# SYSCTRL_GENERAL_CORE register map
Vendor: Texas Instruments
Peripheral module from a debugger description file (folder omap4460).
Registers are 32-bit, access per field, reset values left out (the file's numbers can be read two ways) unless marked. A register's access mark holds for its fields unless they carry their own. Offsets are as the file gives them; lines under a group give offsets from that group; [hi:lo] are bit positions; {n}, {i} and the like mark numbered series; 'fields as' and 'values as' point back to an identical list; <NAME> marks a mode.

## SYSCTRL_GENERAL_CORE
0x00 CONTROL_GEN_CORE_REVISION ro — Control module instance revision identifier
  [31:0] REVISION — IP Revision
0x04 CONTROL_GEN_CORE_HWINFO ro — Information about the IP module hardware configuration
  [31:0] IP_HWINFO — IP-module dependent
0x10 CONTROL_GEN_CORE_SYSCONFIG — Access conditions. Read: unrestricted, Write: unrestricted
  [3:2] IP_SYSCONFIG_IDLEMODE rw — Select the local clock-gating strategy0x2,0x3: Clock is automatically gated when there is no access to the Control Module through L4-interconnect .
    0=Clock is manually gated; 1=Clock is manually enabled
0x200 CONTROL_STD_FUSE_DIE_ID_0 ro — Die ID Register - Part 0. Access conditions. Read: unrestricted
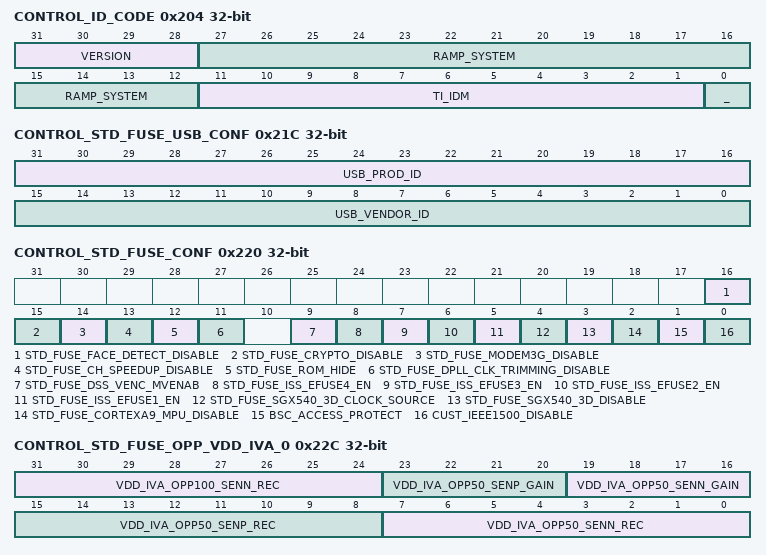
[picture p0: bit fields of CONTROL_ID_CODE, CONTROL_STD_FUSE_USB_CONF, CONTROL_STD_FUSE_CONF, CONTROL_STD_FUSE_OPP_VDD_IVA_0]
0x204 CONTROL_ID_CODE ro — ID_CODE Key Register Access conditions. Read: unrestricted
  [31:28] VERSION — Revision number
  [27:12] RAMP_SYSTEM — Ramp system number
  [11:1] TI_IDM — Manufacturer identity(TI)
  [0] _ — Always set to 1
{0x204+4i} CONTROL_STD_FUSE_DIE_ID_{i} ro (i=1..3) — Die ID Register - Part {i}. Access conditions. Read: unrestricted
0x214 CONTROL_STD_FUSE_PROD_ID_0 ro — Prod ID Register - Part 0. This register shows the device type. Access conditions. Read: unrestricted
  [7:0] DEVICE_TYPE — Define the device type 0xF0 = GP device Other values = Reserved
0x218 CONTROL_STD_FUSE_PROD_ID_1 ro — Prod ID Register - Part 1.This register shows the device type. Access conditions. Read: unrestricted
  [17:16] SILICON_TYPE — Define the silicon performance type
0x21C CONTROL_STD_FUSE_USB_CONF ro — Standard Fuse conf [31:0]. Register shows part of the chip standard eFuse configuration. Reading at the address of one of these registers provides a direct view into a part of the eFuse chain. Access conditions. Read: unrestricted, Write: unrestricted
  [31:16] USB_PROD_ID — USB Product Identification
  [15:0] USB_VENDOR_ID — USB Vendor Identification
0x220 CONTROL_STD_FUSE_CONF ro — Standard fuse configuration register. The register shows part of the chip eFuse configuration on the L4 interface. Reading at the address of one of these registers provides a direct view into a part of the eFuse chain. Access conditions. Read only
  [16] STD_FUSE_FACE_DETECT_DISABLE — Disables face detect
    0=STD_FUSE_FACE_DETECT_DISABLE_0_r (Enables face detect); 1=STD_FUSE_FACE_DETECT_DISABLE_1_r (Disables face detect)
  [15] STD_FUSE_CRYPTO_DISABLE — Disables cryptographic modules
    0=STD_FUSE_CRYPTO_DISABLE_0_r (Enables cryptrographic modules); 1=STD_FUSE_CRYPTO_DISABLE_1_r (Disables cryptrographic modules)
  [14] STD_FUSE_MODEM3G_DISABLE — Disables the 3G modem
    0=STD_FUSE_MODEM3G_DISABLE_0_r (Enables 3G modem); 1=STD_FUSE_MODEM3G_DISABLE_1_r (Disables 3G modem)
  [13] STD_FUSE_CH_SPEEDUP_DISABLE — ROM code settings for configuration header block and speedup block. Only software access (no hardware access).
    0=STD_FUSE_CH_SPEEDUP_DISABLE_0_r (Enables CH and speedup); 1=STD_FUSE_CH_SPEEDUP_DISABLE_1_r (Disables CH and speedup)
  [12] STD_FUSE_ROM_HIDE — MPU BOOT ROM space (4-KB ROM code protection)
    0=STD_FUSE_ROM_HIDE_0_r (BOOT ROM space is 128KB.); 1=STD_FUSE_ROM_HIDE_1_r (BOOT ROM upper 4-KB region becomes reserved.)
  [11] STD_FUSE_DPLL_CLK_TRIMMING_DISABLE — Controls DPLLs
    0=STD_FUSE_DPLL_CLK_TRIMMING_DISABLE_0_r (Enables DPLL trimming); 1=STD_FUSE_DPLL_CLK_TRIMMING_DISABLE_1_r (Disables DPLL trimming)
  [9] STD_FUSE_DSS_VENC_MVENAB — Enables implementation-specific features. Controls DSS_VENC_MVENAB.
    0=STD_FUSE_DSS_VENC_MVENAB_0_r (Disables DSS_VENC_MVENAB); 1=STD_FUSE_DSS_VENC_MVENAB_1_r (Enables DSS_VENC_MVENAB)
  [8] STD_FUSE_ISS_EFUSE4_EN — Enables implementation-specific features. Controls ISS.EFUSE4_EN. Sets to 0.
    0=STD_FUSE_ISS_EFUSE4_EN_0_r (Disables ISS EFUSE4); 1=STD_FUSE_ISS_EFUSE4_EN_1_r (Enables ISS EFUSE4)
  [7] STD_FUSE_ISS_EFUSE3_EN — Enables implementation specific features. Controls ISS.EFUSE3_EN. Sets to 0.
    0=STD_FUSE_ISS_EFUSE3_EN_0_r (Disables ISS EFUSE3); 1=STD_FUSE_ISS_EFUSE3_EN_1_r (Enables ISS EFUSE3)
  [6] STD_FUSE_ISS_EFUSE2_EN — Enables implementation-specific features. Controls ISS.EFUSE2_EN. Sets to 0.
    0=STD_FUSE_ISS_EFUSE2_EN_0_r (Disables ISS EFUSE2); 1=STD_FUSE_ISS_EFUSE2_EN_1_r (Enables ISS EFUSE2)
  [5] STD_FUSE_ISS_EFUSE1_EN — Enables implementation-specific features. Controls ISS.EFUSE1_EN. Sets to 1.
    0=STD_FUSE_ISS_EFUSE1_EN_0_r (Disables ISS EFUSE1); 1=STD_FUSE_ISS_EFUSE1_EN_1_r (Enables ISS EFUSE1)
  [4] STD_FUSE_SGX540_3D_CLOCK_SOURCE — Force 3D graphic engine clock source
  [3] STD_FUSE_SGX540_3D_DISABLE — Disable the 3D Gx engine (SGX540)
    0=STD_FUSE_SGX540_3D_DISABLE_0_r (Enables SGX); 1=STD_FUSE_SGX540_3D_DISABLE_1_r (Disables SGX)
  [2] STD_FUSE_CORTEXA9_MPU_DISABLE — Configures Cortex-A9 MPU boot mode. It disables one Cortex-A9 core.
    0=STD_FUSE_CORTEXA9_MPU_DISABLE_0_r (Boot SMP mode); 1=STD_FUSE_CORTEXA9_MPU_DISABLE_1_r (Boot IP mode)
  [1] BSC_ACCESS_PROTECT — Reserved for bsc_access protect
  [0] CUST_IEEE1500_DISABLE — Customer eFuse control/IEEE1500 access path disable
0x228 CONTROL_STD_FUSE_OPP_VDD_WKUP ro — Standard Fuse OPP VDD_WKUP [31:0]. Register shows part of the chip standard eFuse configuration. Reading at the address of one of these registers provides a direct view into a part of the eFuse chain. Access conditions. Read: unrestricted, Write: unrestricted
  [31:0] STD_FUSE_OPP_VDD_WKUP
0x22C CONTROL_STD_FUSE_OPP_VDD_IVA_0 ro — Standard Fuse OPP VDD_IVA_0. Register shows part of the chip eFuse configuration on the L4 interface. Reading at the address of one of these registers provides a direct view into a part of the eFuse chain. Access conditions. Read: unrestricted, Write: unrestricted
  [31:24] VDD_IVA_OPP100_SENN_REC — Voltage domain VDD_IVA OPP100 [7:0] from Standard Fuse
  [23:20] VDD_IVA_OPP50_SENP_GAIN — Voltage domain VDD_IVA OPP50 [23:20] from Standard Fuse
  [19:16] VDD_IVA_OPP50_SENN_GAIN — Voltage domain VDD_IVA OPP50 [19:16] from Standard Fuse
  [15:8] VDD_IVA_OPP50_SENP_REC — Voltage domain VDD_IVA OPP50 [15:8] from Standard Fuse
  [7:0] VDD_IVA_OPP50_SENN_REC — Voltage domain VDD_IVA OPP50 [7:0] from Standard Fuse
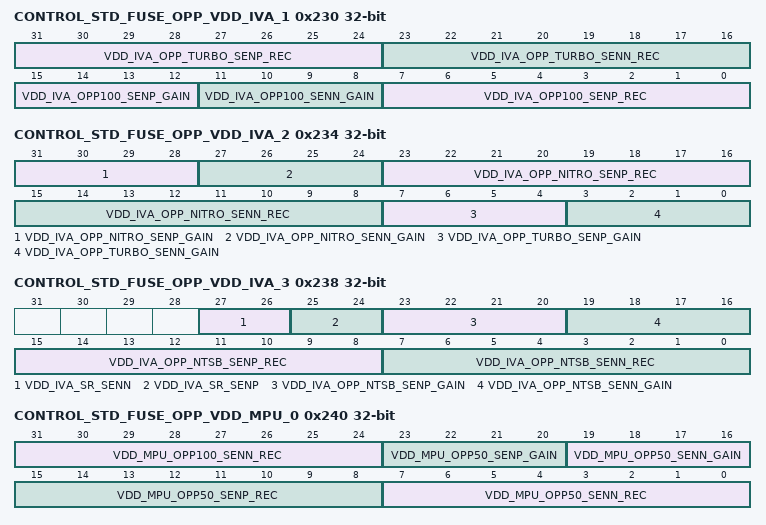
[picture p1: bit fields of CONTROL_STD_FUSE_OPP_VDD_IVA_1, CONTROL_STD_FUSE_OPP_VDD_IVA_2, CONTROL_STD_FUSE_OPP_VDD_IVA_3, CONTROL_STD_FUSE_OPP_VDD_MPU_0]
0x230 CONTROL_STD_FUSE_OPP_VDD_IVA_1 ro — Standard Fuse OPP VDD_IVA_1. Register shows part of the chip eFuse configuration on the L4 interface. Reading at the address of one of these registers provides a direct view into a part of the eFuse chain. Access conditions. Read: unrestricted, Write: unrestricted
  [31:24] VDD_IVA_OPP_TURBO_SENP_REC — Voltage domain VDD_IVA OPP_TURBO [15:8] from Standard Fuse
  [23:16] VDD_IVA_OPP_TURBO_SENN_REC — Voltage domain VDD_IVA OPP_TURBO [7:0] from Standard Fuse
  [15:12] VDD_IVA_OPP100_SENP_GAIN — Voltage domain VDD_IVA OPP100 [23:20] from Standard Fuse
  [11:8] VDD_IVA_OPP100_SENN_GAIN — Voltage domain VDD_IVA OPP100 [19:16] from Standard Fuse
  [7:0] VDD_IVA_OPP100_SENP_REC — Voltage domain VDD_IVA OPP100 [15:8] from Standard Fuse
0x234 CONTROL_STD_FUSE_OPP_VDD_IVA_2 ro — Standard Fuse OPP VDD_IVA_2. Register shows part of the chip eFuse configuration on the L4 interface. Reading at the address of one of these registers provides a direct view into a part of the eFuse chain. Access conditions. Read: unrestricted, Write: unrestricted
  [31:28] VDD_IVA_OPP_NITRO_SENP_GAIN — Voltage domain VDD_IVA OPP_NITRO[23:20] from Standard Fuse
  [27:24] VDD_IVA_OPP_NITRO_SENN_GAIN — Voltage domain VDD_IVA OPP_NITRO[19:16] from Standard Fuse
  [23:16] VDD_IVA_OPP_NITRO_SENP_REC — Voltage domain VDD_IVA OPP_NITRO[15:8] from Standard Fuse
  [15:8] VDD_IVA_OPP_NITRO_SENN_REC — Voltage domain VDD_IVA OPP_NITRO[7:0] from Standard Fuse
  [7:4] VDD_IVA_OPP_TURBO_SENP_GAIN — Voltage domain VDD_IVA OPP_TURBO[23:20] from Standard Fuse
  [3:0] VDD_IVA_OPP_TURBO_SENN_GAIN — Voltage domain VDD_IVA OPP_TURBO[19:16] from Standard Fuse
0x238 CONTROL_STD_FUSE_OPP_VDD_IVA_3 ro — Standard Fuse OPP VDD_IVA_3. Register shows part of the chip eFuse configuration on the L4 interface. Reading at the address of one of these registers provides a direct view into a part of the eFuse chain. Access conditions. Read: unrestricted, Write: unrestricted
  [27:26] VDD_IVA_SR_SENN — VDD_IVA SmartReflex from Standard Fuse
  [25:24] VDD_IVA_SR_SENP — VDD_IVA SmartReflex from Standard Fuse
  [23:20] VDD_IVA_OPP_NTSB_SENP_GAIN — Voltage domain VDD_IVA OPP_NTSB[23:20] from Standard Fuse
  [19:16] VDD_IVA_OPP_NTSB_SENN_GAIN — Voltage domain VDD_IVA OPP_NTSB[19:16] from Standard Fuse
  [15:8] VDD_IVA_OPP_NTSB_SENP_REC — Voltage domain VDD_IVA OPP_NTSB[15:8] from Standard Fuse
  [7:0] VDD_IVA_OPP_NTSB_SENN_REC — Voltage domain VDD_IVA OPP_NTSB[7:0] from Standard Fuse
0x240 CONTROL_STD_FUSE_OPP_VDD_MPU_0 ro — Standard Fuse OPP VDD_MPU_0. Register shows part of the chip eFuse configuration on the L4 interface. Reading at the address of one of these registers provides a direct view into a part of the eFuse chain. Access conditions. Read: unrestricted, Write: unrestricted
  [31:24] VDD_MPU_OPP100_SENN_REC — Voltage domain VDD_MPU OPP100[7:0] from Standard Fuse
  [23:20] VDD_MPU_OPP50_SENP_GAIN — Voltage domain VDD_MPU OPP50[23:20] from Standard Fuse
  [19:16] VDD_MPU_OPP50_SENN_GAIN — Voltage domain VDD_MPU OPP50[19:16] from Standard Fuse
  [15:8] VDD_MPU_OPP50_SENP_REC — Voltage domain VDD_MPU OPP50[15:8] from Standard Fuse
  [7:0] VDD_MPU_OPP50_SENN_REC — Voltage domain VDD_MPU OPP50[7:0] from Standard Fuse
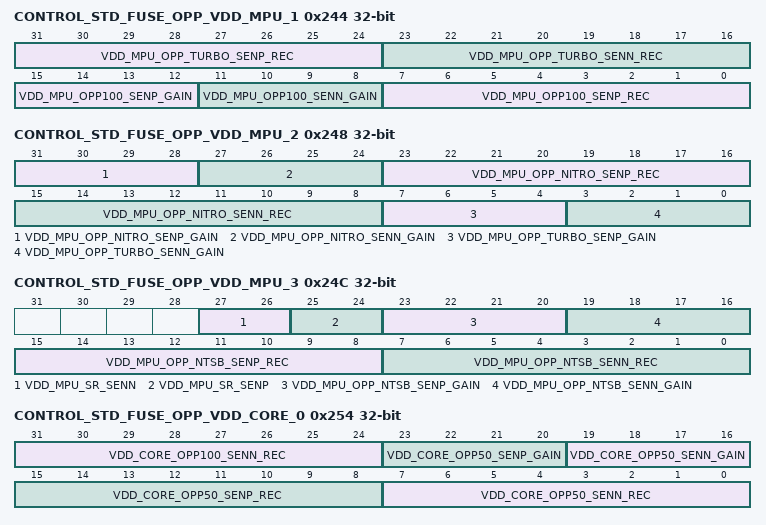
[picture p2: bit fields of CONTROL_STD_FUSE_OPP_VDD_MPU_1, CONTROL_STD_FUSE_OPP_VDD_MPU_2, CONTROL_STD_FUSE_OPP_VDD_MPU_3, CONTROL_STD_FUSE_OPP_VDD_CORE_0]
0x244 CONTROL_STD_FUSE_OPP_VDD_MPU_1 ro — Standard Fuse OPP VDD_MPU_1. Register shows part of the chip eFuse configuration on the L4 interface. Reading at the address of one of these registers provides a direct view into a part of the eFuse chain. Access conditions. Read: unrestricted, Write: unrestricted
  [31:24] VDD_MPU_OPP_TURBO_SENP_REC — Voltage domain VDD_MPU OPP_TURBO[15:8] from Standard Fuse
  [23:16] VDD_MPU_OPP_TURBO_SENN_REC — Voltage domain VDD_MPU OPP_TURBO[7:0] from Standard Fuse
  [15:12] VDD_MPU_OPP100_SENP_GAIN — Voltage domain VDD_MPU OPP100[23:20] from Standard Fuse
  [11:8] VDD_MPU_OPP100_SENN_GAIN — Voltage domain VDD_MPU OPP100[19:16] from Standard Fuse
  [7:0] VDD_MPU_OPP100_SENP_REC — Voltage domain VDD_MPU OPP100[15:8] from Standard Fuse
0x248 CONTROL_STD_FUSE_OPP_VDD_MPU_2 ro — Standard Fuse OPP VDD_MPU_2. Register shows part of the chip eFuse configuration on the L4 interface. Reading at the address of one of these registers provides a direct view into a part of the eFuse chain. Access conditions. Read: unrestricted, Write: unrestricted
  [31:28] VDD_MPU_OPP_NITRO_SENP_GAIN — Voltage domain VDD_MPU OPP_NITRO[23:20] from Standard Fuse
  [27:24] VDD_MPU_OPP_NITRO_SENN_GAIN — Voltage domain VDD_MPU OPP_NITRO[19:16] from Standard Fuse
  [23:16] VDD_MPU_OPP_NITRO_SENP_REC — Voltage domain VDD_MPU OPP_NITRO[15:8] from Standard Fuse
  [15:8] VDD_MPU_OPP_NITRO_SENN_REC — Voltage domain VDD_MPU OPP_NITRO[7:0] from Standard Fuse
  [7:4] VDD_MPU_OPP_TURBO_SENP_GAIN — Voltage domain VDD_MPU OPP_TURBO[23:20] from Standard Fuse
  [3:0] VDD_MPU_OPP_TURBO_SENN_GAIN — Voltage domain VDD_MPU OPP_TURBO[19:16] from Standard Fuse
0x24C CONTROL_STD_FUSE_OPP_VDD_MPU_3 ro — Standard Fuse OPP VDD_MPU_3. Register shows part of the chip eFuse configuration on the L4 interface. Reading at the address of one of these registers provides a direct view into a part of the eFuse chain. Access conditions. Read: unrestricted, Write: unrestricted
  [27:26] VDD_MPU_SR_SENN — VDD_MPU SmartReflex from Standard Fuse
  [25:24] VDD_MPU_SR_SENP — VDD_MPU SmartReflex from Standard Fuse
  [23:20] VDD_MPU_OPP_NTSB_SENP_GAIN — Voltage domain VDD_MPU OPP_NTSB[23:20] from Standard Fuse
  [19:16] VDD_MPU_OPP_NTSB_SENN_GAIN — Voltage domain VDD_MPU OPP_NTSB[19:16] from Standard Fuse
  [15:8] VDD_MPU_OPP_NTSB_SENP_REC — Voltage domain VDD_MPU OPP_NTSB[15:8] from Standard Fuse
  [7:0] VDD_MPU_OPP_NTSB_SENN_REC — Voltage domain VDD_MPU OPP_NTSB[7:0] from Standard Fuse
0x254 CONTROL_STD_FUSE_OPP_VDD_CORE_0 ro — Standard Fuse OPP VDD_CORE_0. Register shows part of the chip eFuse configuration on the L4 interface. Reading at the address of one of these registers provides a direct view into a part of the eFuse chain. Access conditions. Read: unrestricted, Write: unrestricted
  [31:24] VDD_CORE_OPP100_SENN_REC — Voltage domain VDD_CORE OPP100[7:0] from Standard Fuse
  [23:20] VDD_CORE_OPP50_SENP_GAIN — Voltage domain VDD_CORE OPP50 23:20] from Standard Fuse
  [19:16] VDD_CORE_OPP50_SENN_GAIN — Voltage domain VDD_CORE OPP50[19:16] from Standard Fuse
  [15:8] VDD_CORE_OPP50_SENP_REC — Voltage domain VDD_CORE OPP50[15:8] from Standard Fuse
  [7:0] VDD_CORE_OPP50_SENN_REC — Voltage domain VDD_CORE OPP50[7:0] from Standard Fuse
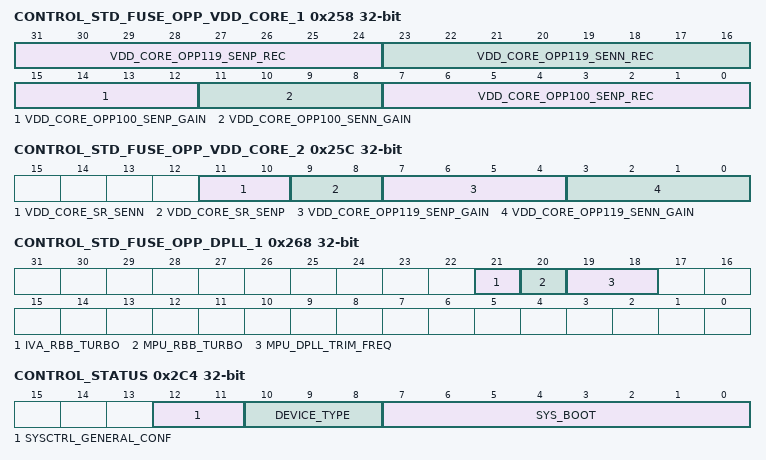
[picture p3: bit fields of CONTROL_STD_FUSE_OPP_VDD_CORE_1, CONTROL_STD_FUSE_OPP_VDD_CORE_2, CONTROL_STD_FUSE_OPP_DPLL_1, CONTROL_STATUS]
0x258 CONTROL_STD_FUSE_OPP_VDD_CORE_1 ro — Standard Fuse OPP VDD_CORE_1. Register shows part of the chip eFuse configuration on the L4 interface. Reading at the address of one of these registers provides a direct view into a part of the eFuse chain. Access conditions. Read: unrestricted, Write: unrestricted
  [31:24] VDD_CORE_OPP119_SENP_REC — Voltage domain VDD_CORE OPP119[15:8] from Standard Fuse (overdrive mode)
  [23:16] VDD_CORE_OPP119_SENN_REC — Voltage domain VDD_CORE OPP119[7:0] from Standard Fuse (overdrive mode)
  [15:12] VDD_CORE_OPP100_SENP_GAIN — Voltage domain VDD_CORE OPP100[23:20] from Standard Fuse
  [11:8] VDD_CORE_OPP100_SENN_GAIN — Voltage domain VDD_CORE OPP100[19:16] from Standard Fuse
  [7:0] VDD_CORE_OPP100_SENP_REC — Voltage domain VDD_CORE OPP100[15:8] from Standard Fuse
0x25C CONTROL_STD_FUSE_OPP_VDD_CORE_2 ro — Standard Fuse OPP VDD_CORE_2. Register shows part of the chip eFuse configuration on the L4 interface. Reading at the address of one of these registers provides a direct view into a part of the eFuse chain. Access conditions. Read: unrestricted, Write: unrestricted
  [11:10] VDD_CORE_SR_SENN — VDD_CORE SmartReflex from Standard Fuse
  [9:8] VDD_CORE_SR_SENP — VDD_CORE SmartReflex from Standard Fuse
  [7:4] VDD_CORE_OPP119_SENP_GAIN — Voltage domain VDD_CORE OPP119[23:20] from Standard Fuse (overdrive mode)
  [3:0] VDD_CORE_OPP119_SENN_GAIN — Voltage domain VDD_CORE OPP119[19:16] from Standard Fuse (overdrive mode)
0x260 CONTROL_STD_FUSE_OPP_BGAP ro — Standard Fuse OPP BGAP. Register shows part of the chip standard eFuse configuration. Reading at the address of one of these registers provides a direct view into a part of the eFuse chain. Access conditions. Read: unrestricted, Write: unrestricted
  [31:0] STD_FUSE_OPP_BGAP
0x264 CONTROL_STD_FUSE_OPP_DPLL_0 ro — Standard Fuse OPP DPLL. Register shows part of the chip standard eFuse configuration. Reading at the address of one of these registers provides a direct view into a part of the eFuse chain. Access conditions. Read: unrestricted, Write: unrestricted
  [31:0] STD_FUSE_OPP_DPLL_0
0x268 CONTROL_STD_FUSE_OPP_DPLL_1 ro — Standard Fuse OPP DPLL. Register shows part of the chip standard eFuse configuration. Reading at the address of one of these registers provides a direct view into a part of the eFuse chain. Access conditions. Read: unrestricted, Write: unrestricted
  [21] IVA_RBB_TURBO — If trimmed, ABB (Adaptive Body Bias) Set2 mode can be enabled at OPP TURBO on IVA
    0=IVA ABB Set2 voltage is NOT trimmed; 1=IVA ABB Set2 voltage is trimmed
  [20] MPU_RBB_TURBO — If trimmed, ABB Set2 mode can be enabled at OPP TURBO on MPU.
    0=MPU ABB Set2 voltage is NOT trimmed; 1=MPU ABB Set2 voltage is trimmed
  [19:18] MPU_DPLL_TRIM_FREQ — Lock frequency at which the MPU DPLL is trimmed. The DPLL can be locked at any valid frequencies up to this value.
    0=2 GHz; 1=2.4 GHz; 3=3 GHz
0x2C4 CONTROL_STATUS ro — Control Module Status Register Access conditions. Read: unrestricted, Write: unrestricted
  [12:11] SYSCTRL_GENERAL_CONF — Sysctrl_General_ IP configuration
    1=SYSCTRL_GENERAL_CONF_1_r (SMP configuration)
  [10:8] DEVICE_TYPE — Device type captured at reset time Device type value sampled at power-on reset.
    3=DEVICE_TYPE_3_r (General Purpose (GP))
  [7:0] SYS_BOOT — Sys.Boot pins state captured at reset time Sys.Boot pin values sampled at power-on reset
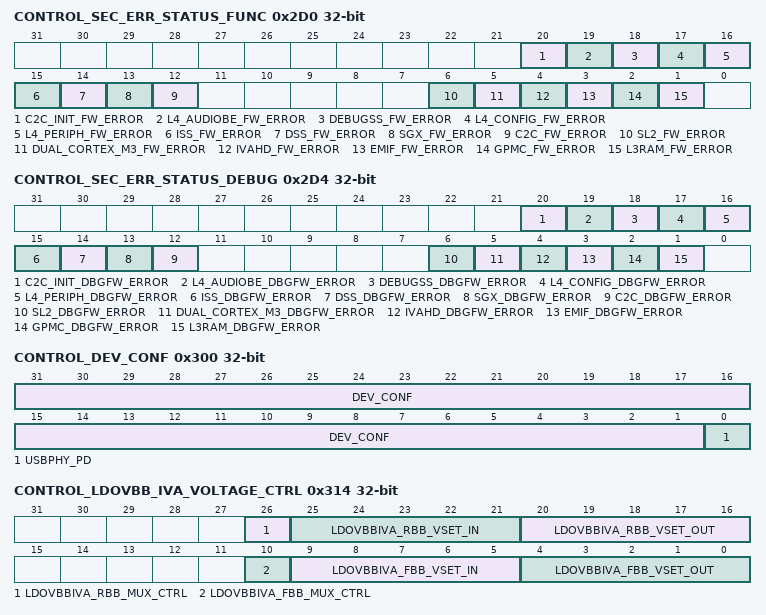
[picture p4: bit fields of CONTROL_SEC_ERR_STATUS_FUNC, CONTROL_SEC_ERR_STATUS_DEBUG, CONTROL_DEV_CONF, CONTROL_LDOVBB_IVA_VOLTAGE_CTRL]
0x2D0 CONTROL_SEC_ERR_STATUS_FUNC ro — Firewall Error Status functional Register Access conditions. Read Only
  [all] fields
    0=No error from firewall; 1=Error from firewall
  [20] C2C_INIT_FW_ERROR — C2C init firewall. MID config: unused (reserved)
  [19] L4_AUDIOBE_FW_ERROR — L4 AudioBE firewall
  [18] DEBUGSS_FW_ERROR — DebugSS firewall
  [17] L4_CONFIG_FW_ERROR — L4 Config firewall
  [16] L4_PERIPH_FW_ERROR — L4 PER firewall
  [15] ISS_FW_ERROR — ISS firewall
  [14] DSS_FW_ERROR — DSS firewall
  [13] SGX_FW_ERROR — SGX firewall
  [12] C2C_FW_ERROR — C2C firewall. MID config: unused (reserved).
  [6] SL2_FW_ERROR — SL2 firewall
  [5] DUAL_CORTEX_M3_FW_ERROR — Dual Cortex M3 firewall
  [4] IVAHD_FW_ERROR — IVAHD firewall
  [3] EMIF_FW_ERROR — EMIF firewall
  [2] GPMC_FW_ERROR — GPMC firewall
  [1] L3RAM_FW_ERROR — L3RAM firewall
0x2D4 CONTROL_SEC_ERR_STATUS_DEBUG ro — Error Status debug Register. Read All / Write All. Access conditions. Read: unrestricted, Write: unrestricted
  [all] fields
    0=No error from firewall; 1=Error from firewall
  [20] C2C_INIT_DBGFW_ERROR — C2C init debug firewall. MID config: unused (reserved)
  [19] L4_AUDIOBE_DBGFW_ERROR — L4 AudioBE debug firewall
  [18] DEBUGSS_DBGFW_ERROR — DebugSS debug firewall
  [17] L4_CONFIG_DBGFW_ERROR — L4 Config debug firewall
  [16] L4_PERIPH_DBGFW_ERROR — L4 PER debug firewall
  [15] ISS_DBGFW_ERROR — ISS debug firewall
  [14] DSS_DBGFW_ERROR — DSS debug firewall
  [13] SGX_DBGFW_ERROR — SGX debug firewall
  [12] C2C_DBGFW_ERROR — C2C debug firewall. MID config: unused (reserved).
  [6] SL2_DBGFW_ERROR — SL2 debug firewall
  [5] DUAL_CORTEX_M3_DBGFW_ERROR — Dual Cortex M3 debug firewall
  [4] IVAHD_DBGFW_ERROR — IVAHD debug firewall
  [3] EMIF_DBGFW_ERROR — EMIF debug firewall
  [2] GPMC_DBGFW_ERROR — GPMC debug firewall
  [1] L3RAM_DBGFW_ERROR — L3RAM debug firewall
0x300 CONTROL_DEV_CONF rw — Device configuration register. Access conditions. Read: unrestricted, Write: unrestricted
  [31:1] DEV_CONF — Spare bits for device configuration.
  [0] USBPHY_PD — Power down entire USB phy (data, common module and UTMI). controls USB2PHYCORE.PD pin.
    0=Normal operation; 1=Power down the USB PHY
0x314 CONTROL_LDOVBB_IVA_VOLTAGE_CTRL — IVA Voltage Body Bias LDO control register Access conditions. Read: unrestricted, Write: unrestricted
  [26] LDOVBBIVA_RBB_MUX_CTRL rw — Override control of EFUSE Adaptive Body Bias set2 voltage value
    0=EFUSE value is used; 1=Override value is used
  [25:21] LDOVBBIVA_RBB_VSET_IN ro — EFUSE Adaptive Body Bias set2 voltage value
  [20:16] LDOVBBIVA_RBB_VSET_OUT rw — Override value for Adaptive Body Bias set2 voltage
  [10] LDOVBBIVA_FBB_MUX_CTRL rw — Override control of EFUSE Adaptive Body Bias Set1 voltage value
    0=EFUSE value is used; 1=Override value is used
  [9:5] LDOVBBIVA_FBB_VSET_IN ro — EFUSE Adaptive Body Bias Set1 voltage value
  [4:0] LDOVBBIVA_FBB_VSET_OUT rw — Override value for Adaptive Body Bias Set1 voltage
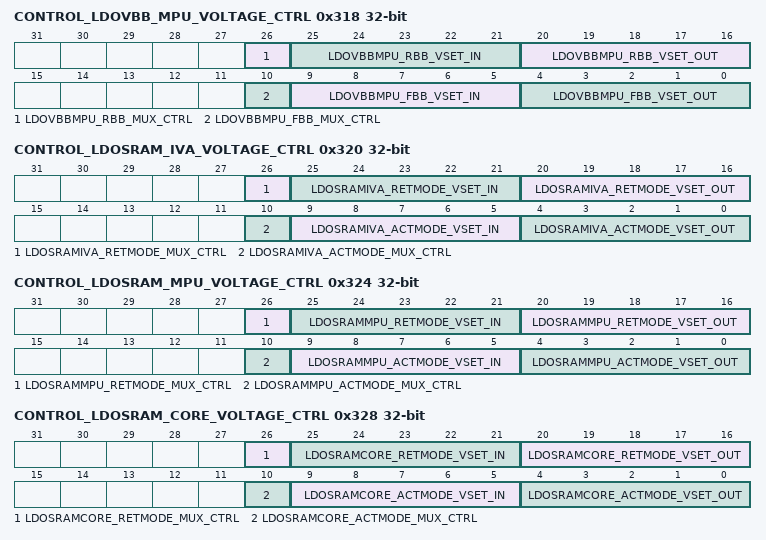
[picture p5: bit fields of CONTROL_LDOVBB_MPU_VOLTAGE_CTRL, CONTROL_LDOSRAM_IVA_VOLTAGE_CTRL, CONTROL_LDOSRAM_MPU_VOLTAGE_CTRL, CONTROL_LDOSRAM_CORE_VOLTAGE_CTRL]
0x318 CONTROL_LDOVBB_MPU_VOLTAGE_CTRL — MPU Voltage Body Bias LDO control register Access conditions. Read: unrestricted, Write: unrestricted
  [26] LDOVBBMPU_RBB_MUX_CTRL rw — Override control of EFUSE Adaptive Body Bias Set2 voltage value
    0=EFUSE value is used; 1=Override value is used
  [25:21] LDOVBBMPU_RBB_VSET_IN ro — EFUSE Adaptive Body Bias Set2 voltage value
  [20:16] LDOVBBMPU_RBB_VSET_OUT rw — Override value for Adaptive Body Bias Set2 voltage
  [10] LDOVBBMPU_FBB_MUX_CTRL rw — Override control of EFUSE Adaptive Body Bias Set1 voltage value
    0=EFUSE value is used; 1=Override value is used
  [9:5] LDOVBBMPU_FBB_VSET_IN ro — EFUSE Adaptive Body Bias Set1 voltage value
  [4:0] LDOVBBMPU_FBB_VSET_OUT rw — Override value for Adaptive Body Bias Set1 voltage
0x320 CONTROL_LDOSRAM_IVA_VOLTAGE_CTRL — IVA SRAM LDO control register Access conditions. Read: unrestricted, Write: unrestricted
  [26] LDOSRAMIVA_RETMODE_MUX_CTRL rw — Override control of EFUSE Retention Mode Voltage value
    0=efuse value is used; 1=override value is used
  [25:21] LDOSRAMIVA_RETMODE_VSET_IN ro — EFUSE Retention Mode Voltage value (vset[9:5])
  [20:16] LDOSRAMIVA_RETMODE_VSET_OUT rw — Override value for Retention Mode Voltage
  [10] LDOSRAMIVA_ACTMODE_MUX_CTRL rw — Override control of EFUSE Active Mode Voltage value
    0=efuse value is used; 1=override value is used
  [9:5] LDOSRAMIVA_ACTMODE_VSET_IN ro — EFUSE Active Mode Voltage value (vset[4:0])
  [4:0] LDOSRAMIVA_ACTMODE_VSET_OUT rw — Override value for Active Mode Voltage value
0x324 CONTROL_LDOSRAM_MPU_VOLTAGE_CTRL — MPU SRAM LDO control register Access conditions. Read: unrestricted, Write: unrestricted
  [26] LDOSRAMMPU_RETMODE_MUX_CTRL rw — Override control of EFUSE Retention Mode Voltage value
    0=efuse value is used; 1=override value is used
  [25:21] LDOSRAMMPU_RETMODE_VSET_IN ro — EFUSE Retention Mode Voltage value (vset[9:5])
  [20:16] LDOSRAMMPU_RETMODE_VSET_OUT rw — Override value for Retention Mode Voltage
  [10] LDOSRAMMPU_ACTMODE_MUX_CTRL rw — Override control of EFUSE Active Mode Voltage value
    0=efuse value is used; 1=override value is used
  [9:5] LDOSRAMMPU_ACTMODE_VSET_IN ro — EFUSE Active Mode Voltage value (vset[4:0])
  [4:0] LDOSRAMMPU_ACTMODE_VSET_OUT rw — Override value for Active Mode Voltage value
0x328 CONTROL_LDOSRAM_CORE_VOLTAGE_CTRL — Core SRAM LDO control register Access conditions. Read: unrestricted, Write: unrestricted
  [26] LDOSRAMCORE_RETMODE_MUX_CTRL rw — Override control of EFUSE Retention Mode Voltage value
    0=efuse value is used; 1=override value is used
  [25:21] LDOSRAMCORE_RETMODE_VSET_IN ro — EFUSE Retention Mode Voltage value (vset[9:5])
  [20:16] LDOSRAMCORE_RETMODE_VSET_OUT rw — Override value for Retention Mode Voltage
  [10] LDOSRAMCORE_ACTMODE_MUX_CTRL rw — Override control of EFUSE Active Mode Voltage value
    0=efuse value is used; 1=override value is used
  [9:5] LDOSRAMCORE_ACTMODE_VSET_IN ro — EFUSE Active Mode Voltage value (vset[4:0])
  [4:0] LDOSRAMCORE_ACTMODE_VSET_OUT rw — Override value for Active Mode Voltage value
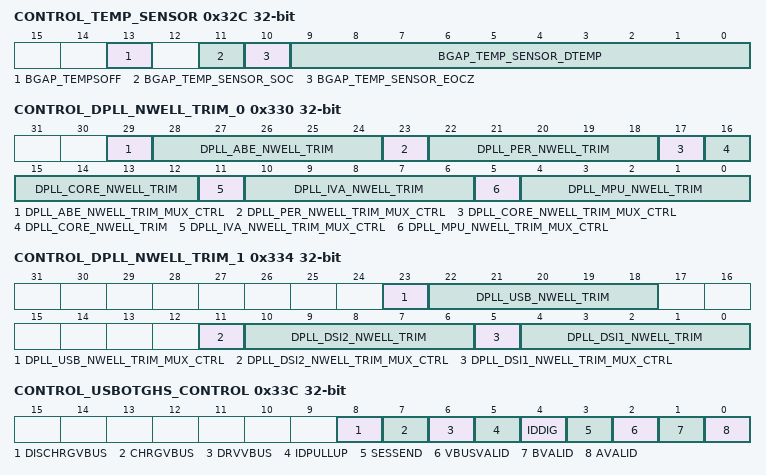
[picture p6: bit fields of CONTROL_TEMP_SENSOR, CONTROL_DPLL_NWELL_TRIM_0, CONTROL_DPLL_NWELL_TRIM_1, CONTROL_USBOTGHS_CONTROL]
0x32C CONTROL_TEMP_SENSOR — Control VBGAPTS temperature sensor and thermal comparator shutdown register Access conditions. Read: unrestricted, Write: unrestricted
  [13] BGAP_TEMPSOFF rw — Temperature sensor and thermal shutdown mode.
    0=Temperature sensor and thermal shutdown is active; 1=Temperature sensor and thermal shutdown set in OFF mode
  [11] BGAP_TEMP_SENSOR_SOC rw — ADC Start of Conversion. A transition to high starts a new ADC conversion cycle
  [10] BGAP_TEMP_SENSOR_EOCZ ro — ADC End of Conversion. Active low, when CTRL_ TEMP(5:0) is valid.
  [9:0] BGAP_TEMP_SENSOR_DTEMP ro — Temperature data from the ADC. Valid if EOCZ is low.
0x330 CONTROL_DPLL_NWELL_TRIM_0 — Dpll trim (SW override) - Part 0 Access conditions. Read: unrestricted, Write: unrestricted
  [29] DPLL_ABE_NWELL_TRIM_MUX_CTRL rw — Software override selection over efuse values.
    0=efuse value is used; 1=override value is used
  [28:24] DPLL_ABE_NWELL_TRIM rw — Software override value.
  [23] DPLL_PER_NWELL_TRIM_MUX_CTRL rw — Software override selection over efuse values.
    0=efuse value is used; 1=override value is used
  [22:18] DPLL_PER_NWELL_TRIM rw — Software override value.
  [17] DPLL_CORE_NWELL_TRIM_MUX_CTRL rw — Software override selection over efuse values.
    0=efuse value is used; 1=override value is used
  [16:12] DPLL_CORE_NWELL_TRIM rw — Software override value.
  [11] DPLL_IVA_NWELL_TRIM_MUX_CTRL rw — Software override selection over efuse values.
    0=efuse value is used; 1=override value is used
  [10:6] DPLL_IVA_NWELL_TRIM rw — Software override value.
  [5] DPLL_MPU_NWELL_TRIM_MUX_CTRL rw — Software override selection over efuse values.
    0=efuse value is used; 1=override value is used
  [4:0] DPLL_MPU_NWELL_TRIM rw — Software override value.
0x334 CONTROL_DPLL_NWELL_TRIM_1 — Dpll trim (SW override) - Part 1 Access conditions. Read: unrestricted, Write: unrestricted
  [23] DPLL_USB_NWELL_TRIM_MUX_CTRL rw — Software override selection over efuse values.
    0=efuse value is used; 1=override value is used
  [22:18] DPLL_USB_NWELL_TRIM rw — Software override value.
  [11] DPLL_DSI2_NWELL_TRIM_MUX_CTRL rw — Software override selection over efuse values.
    0=efuse value is used; 1=override value is used
  [10:6] DPLL_DSI2_NWELL_TRIM rw — Software override value.
  [5] DPLL_DSI1_NWELL_TRIM_MUX_CTRL rw — Software override selection over efuse values.
    0=efuse value is used; 1=override value is used
  [4:0] DPLL_DSI1_NWELL_TRIM rw — Software override value.
0x33C CONTROL_USBOTGHS_CONTROL — USBOTGHS software control Access conditions. Read: unrestricted, Write: unrestricted
  [8] DISCHRGVBUS ro — USBOTGHS value for signal dischrgvbus (OTG_PD_VBUS ). controls discharging of VBUS for completing SRP.
    0=DISCHRGVBUS_0_r (OTG transceiver does not discharge VBUS); 1=DISCHRGVBUS_1_r (OTG transceiver discharges VBUS)
  [7] CHRGVBUS ro — USBOTGHS value for signal chrgvbus (OTG_PU_VBUS). controls charging of VBUS for initiating SRP.
    0=CHRGVBUS_0_r (OTG transceiver does not charge VBUS); 1=CHRGVBUS_1_r (OTG transceiver charges VBUS)
  [6] DRVVBUS ro — USBOTGHS value for signal drvvbus (OTG_DRV_VBUS). controls the driving of 5V power on VBUS.
    0=DRVVBUS_0_r (OTG transceiver does not drive VBUS); 1=DRVVBUS_1_r (OTG transceiver drives VBUS)
  [5] IDPULLUP ro — USBOTGHS value for signal Idpullup (OTG_PU_ID). Enables sampling of the ID pin of the USB connector.
    0=IDPULLUP_0_r (OTG transceiver does not apply a pullup to ID); 1=IDPULLUP_1_r (OTG transceiver applies a pullup to ID)
  [4] IDDIG rw — Sets the USBOTGHS signal iddig (ID). Indicates the value of the ID pin of the USB connector.
    0=ID pin is grounded; 1=ID pin is high-impedance
  [3] SESSEND rw — Sets the USBOTGHS signal sessend (BSESSEND). Indicates if VBUS is below the B-Device session end threshold. The threshold Vth is between 0.2V and 0.8V.
    0=VBUS voltage is above VB_SESS_END; 1=VBUS voltage is below VB_SESS_END
  [2] VBUSVALID rw — Sets the USBOTGHS signal vbusvalid (VBUSVLD). Indicates if VBUS is above the threshold for normal operation. The threshold Vth is between 4.4V and 4.75V.
  [1] BVALID rw — Sets the USBOTGHS signal bvalid (BSESSVLD). Signal is currently unconnected (reserved for future use).
    0=VBUS voltage is below VB_SESS_VLD; 1=VBUS voltage is above VB_SESS_VLD
  [0] AVALID rw — Sets the USBOTGHS signal avalid (ASESSVLD). Indicates if VBUS is above the A-Device session valid threshold. The threshold Vth is between 0.8V and 2.0V.
    0=VBUS voltage is below VA_SESS_VLD; 1=VBUS voltage is above VA_SESS_VLD
0x340 CONTROL_DSS_CONTROL — DSS software control Access conditions. Read: unrestricted, Write: unrestricted
  [0] DSS_MUX6_SELECT rw — Mux6 select value for DSS.
    0=enables DSS_CLK as functional clock input for the DSI2 PHY bypass clock; 1=enables PLL1_CLK4 as functional clock input for the DSI2 PHY bypass clock
0x348 CONTROL_CORTEX_M3_MMUADDRTRANSLTR — CORTEX_M3 reg Access conditions. Read: unrestricted, Write: unrestricted
  [19:0] CORTEX_M3_MMUADDRTRANSLTR rw — Used to save the mmu address boot
0x34C CONTROL_CORTEX_M3_MMUADDRLOGICTR — Access conditions. Read: unrestricted, Write: unrestricted
  [19:0] CORTEX_M3_MMUADDRLOGICTR rw
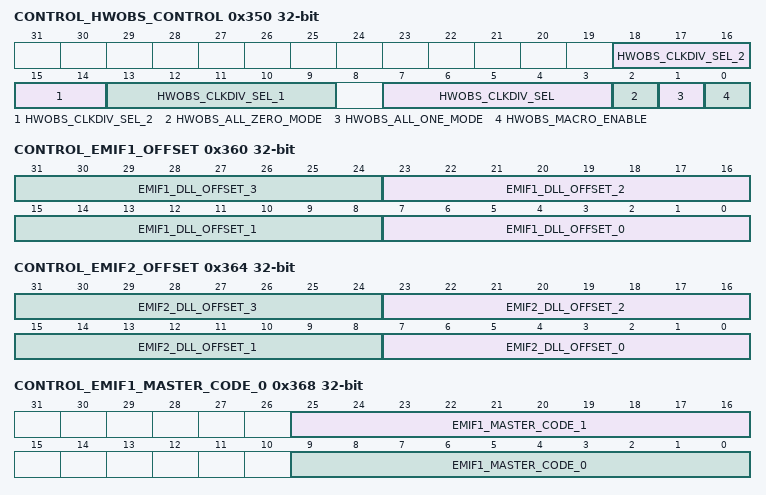
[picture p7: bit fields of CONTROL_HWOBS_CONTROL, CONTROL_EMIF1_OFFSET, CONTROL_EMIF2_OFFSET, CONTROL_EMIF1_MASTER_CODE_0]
0x350 CONTROL_HWOBS_CONTROL — Hardware observability control. This register enables or disables hardware observability outputs (to save power primarily) Access conditions. Read: unrestricted, Write: unrestricted
  [18:14] HWOBS_CLKDIV_SEL_2 rw — Clock divider selection on po_hwobs(2).
    1=output is not divided; 2=output is divided by 2; 4=output is divided by 4; 8=output is divided by 8; 16=output is divided by 16
  [13:9] HWOBS_CLKDIV_SEL_1 rw — Clock divider selection on po_hwobs(1).
    values as HWOBS_CLKDIV_SEL_2
  [7:3] HWOBS_CLKDIV_SEL rw — Clock divider selection on po_hwobs(0).
    values as HWOBS_CLKDIV_SEL_2
  [2] HWOBS_ALL_ZERO_MODE rw — Used to gate observable signals. When set all outputs are set to zero (can be used to check the path from hardware observability to external pads).
    0=Hardware observability ports are not gated; 1=Hardware observability ports are all set to 0
  [1] HWOBS_ALL_ONE_MODE rw — Used to gate observable signals. When set all outputs are set to one (can be used to check the path from hardware observability to external pads).
    0=Hardware observability ports are not gated; 1=Hardware observability ports are all set to 1
  [0] HWOBS_MACRO_ENABLE rw — Used to gate observable signals coming from macros using the 32-bit HWOBS bus definition. When deasserted all outputs of the HWOBS busdef are set to zero.
    0=Hardware observability ports from macros are gated and set to zero; 1=Hardware observability ports from macros are not gated
0x360 CONTROL_EMIF1_OFFSET rw — emif1 offset Access conditions. Read: unrestricted, Write: unrestricted
  [8n+7:8n] EMIF1_DLL_OFFSET_{n} (n=0..3) — 8-bit signed offset value (-128 ... +127) for EMIF1 DLL Slave{n} delay correction.
0x364 CONTROL_EMIF2_OFFSET rw — emif2 offset Access conditions. Read: unrestricted, Write: unrestricted
  [8n+7:8n] EMIF2_DLL_OFFSET_{n} (n=0..3) — 8-bit signed offset value (-128 ... +127) for EMIF2 DLL Slave{n} delay correction.
0x368 CONTROL_EMIF1_MASTER_CODE_0 ro — emif1 master code Access conditions. Read: unrestricted, Write: unrestricted
  [25:16] EMIF1_MASTER_CODE_1 — EMIF1 DLL Master1 code
  [9:0] EMIF1_MASTER_CODE_0 — EMIF1 DLL Master0 code
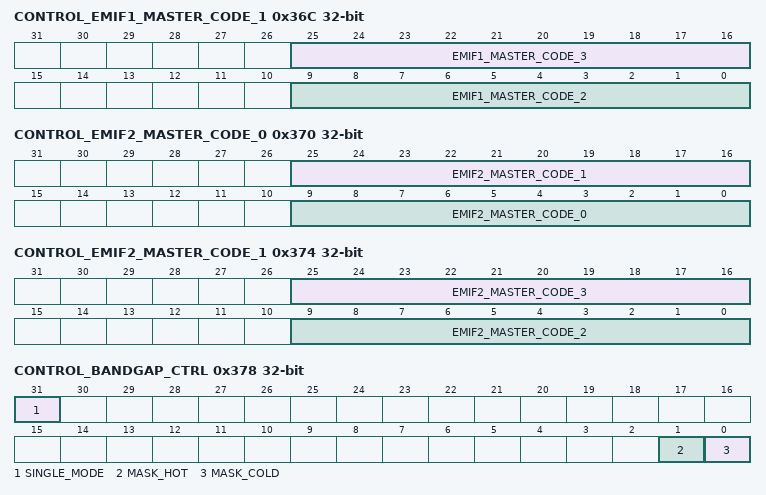
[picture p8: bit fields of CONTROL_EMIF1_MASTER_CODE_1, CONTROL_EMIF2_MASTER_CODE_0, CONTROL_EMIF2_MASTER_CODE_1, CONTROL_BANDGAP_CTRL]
0x36C CONTROL_EMIF1_MASTER_CODE_1 ro — Access conditions. Read: unrestricted, Write: unrestricted
  [25:16] EMIF1_MASTER_CODE_3 — EMIF1 DLL Master3 code
  [9:0] EMIF1_MASTER_CODE_2 — EMIF1 DLL Master2 code
0x370 CONTROL_EMIF2_MASTER_CODE_0 ro — emif2 master code Access conditions. Read: unrestricted, Write: unrestricted
  [25:16] EMIF2_MASTER_CODE_1 — EMIF2 DLL Master1 code
  [9:0] EMIF2_MASTER_CODE_0 — EMIF2 DLL Master0 code
0x374 CONTROL_EMIF2_MASTER_CODE_1 ro — Access conditions. Read: unrestricted, Write: unrestricted
  [25:16] EMIF2_MASTER_CODE_3 — EMIF2 DLL Master3 code
  [9:0] EMIF2_MASTER_CODE_2 — EMIF2 DLL Master2 code
0x378 CONTROL_BANDGAP_CTRL — bandgap control Access conditions. Read: unrestricted, Write: unrestricted
  [31] SINGLE_MODE rw — Toggles between single mode or continuous mode (repeated single mode)
    0=Single mode selected; 1=Continuous mode selected
  [1] MASK_HOT rw — Mask for hot events
    0=hot event is masked; 1=hot event is enabled
  [0] MASK_COLD rw — Mask for cold events
    0=cold event is masked; 1=cold event is enabled
0x37C CONTROL_BANDGAP_COUNTER — bandgap counter Access conditions. Read: unrestricted, Write: unrestricted
  [23:0] COUNTER rw — Counter for continous mode
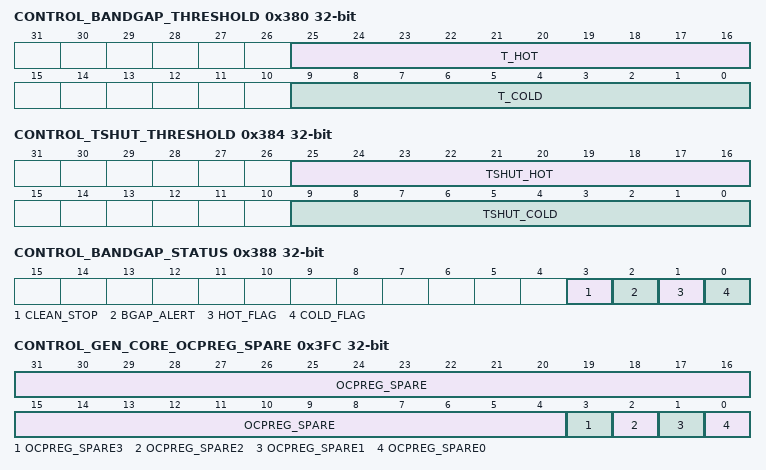
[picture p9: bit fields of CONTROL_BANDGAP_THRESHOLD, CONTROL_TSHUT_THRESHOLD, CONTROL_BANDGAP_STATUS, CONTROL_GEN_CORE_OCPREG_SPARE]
0x380 CONTROL_BANDGAP_THRESHOLD — bandgap threshold Access conditions. Read: unrestricted, Write: unrestricted
  [25:16] T_HOT rw — Threshold for hot temperature
  [9:0] T_COLD rw — Threshold for cold temperature
0x384 CONTROL_TSHUT_THRESHOLD — bandgap tshut threshold Access conditions. Read: unrestricted, Write: unrestricted
  [25:16] TSHUT_HOT rw — Tshut Threshold for hot temperature. Code value must not exceed the device junction (hottest spot) maximal-allowed temperature minus the device temperature sensor offset estimated at current conditions. For more information, see , .
  [9:0] TSHUT_COLD rw — Tshut Threshold for cold temperature
0x388 CONTROL_BANDGAP_STATUS ro — bandgap status Access conditions. Read: unrestricted, Write: unrestricted
  [3] CLEAN_STOP — Show when clean stop
  [2] BGAP_ALERT — Show when hot or cold event
  [1] HOT_FLAG — Show when hot event
  [0] COLD_FLAG — Show when cold event
0x3C0 CONTROL_FORCEWRNP — Access conditions. Read: unrestricted, Write: unrestricted
  [0] MPUFORCEWRNP rw — 0x0: Non-posted write attribute is defined by Cortex-A9 CPU 0x1: Forces only non-posted write commands from MPUSS to the L3 interconnect
0x3FC CONTROL_GEN_CORE_OCPREG_SPARE — The lower 4-bits of this register are assigned to control PWRDN mode globally, and the LVCMOS buffers enable control of the EMIF1 and EMIF2 PHYs. Read: Unrestricted; Write: Unrestricted
  [31:4] OCPREG_SPARE ro — Reserved
  [3] OCPREG_SPARE3 rw — emif2phydata0–emif2phydata3 power-down mode control
    0=Normal mode selected; 1=Power-down mode selected
  [2] OCPREG_SPARE2 rw — emif2phycmd0, emif2phydata0–emif2phydata3 I/O LVCMOS buffers enable
    0=Differential comparator is enabled; 1=Differential comparator is disabled
  [1] OCPREG_SPARE1 rw — emif1phydata0–emif1phydata3 power-down mode control
    0=Normal mode is selected; 1=Power-down mode is selected
  [0] OCPREG_SPARE0 rw — emif1phycmd0, emif1phydata0–emif1phydata3 I/O LVCMOS buffers enable
    0=LVCMOS buffers are enabled; 1=LVCMOS buffers are disabled
0x400 CONTROL_DEBOBS_FINAL_MUX_SEL rw — Final mux select signal. It selects between core and wkup signal (controls external observability logic). Access conditions. Read: unrestricted, Write: unrestricted
  [31:0] SELECT — The i-th (i=0..31) bit from this bit field controls the multiplexing between the core and the wake-up signals to be observed at i-th hw_dbg line.
0x408 CONTROL_DEBOBS_MMR_MPU — Dual Cortex-A9 register to control hardware observability muxing inside dual Cortex-A9 (controls external observability logic).
  [3:0] SELECT rw — Control external observability logic
{0x42C+4i} CONTROL_CONF_SDMA_REQ_SEL{i} (i=0..3) — System DMA requests view channel {i} Access conditions. Read: unrestricted, Write: unrestricted
  [6:0] MULT rw — Select one of the following signals:
    {v}=hwobs_sdma_dma_req_{v} (v=0..126)
{0x440+4i} CONTROL_CONF_CLK_SEL{i} (i=0..2) — clk view channel {i} Access conditions. Read: unrestricted, Write: unrestricted
  [2:0] MULT rw — Select one of the following signals:
    0=hwobs_coredpll_clkout; 1=hwobs_abedpll_clkout; 2=hwobs_perdpll_clkout; 3=hwobs_dsi1dpll_clkout; 4=hwobs_dsi2dpll_clkout; 6=hwobs_usbdpll_clkout
0x44C CONTROL_CONF_DPLL_FREQLOCK_SEL — dpll_freqlock view Access conditions. Read: unrestricted, Write: unrestricted
  [2:0] MULT rw — Select one of the following signals:
    0=hwobs_coredpll_freqlock; 1=hwobs_abedpll_freqlock; 2=hwobs_perdpll_freqlock; 3=hwobs_dsi1dpll_freqlock; 4=hwobs_dsi2dpll_freqlock; 6=hwobs_usbdpll_freqlock
0x450 CONTROL_CONF_DPLL_TINITZ_SEL — dpll_tinitz view Access conditions. Read: unrestricted, Write: unrestricted
  [2:0] MULT rw — Select one of the following signals:
    0=hwobs_coredpll_tinitz
0x454 CONTROL_CONF_DPLL_PHASELOCK_SEL — dpll_phaselock view Access conditions. Read: unrestricted, Write: unrestricted
  [2:0] MULT rw — Select one of the following signals:
    0=hwobs_coredpll_phaselock; 1=hwobs_abedpll_phaselock; 2=hwobs_perdpll_phaselock; 3=hwobs_dsi1dpll_phaselock; 4=hwobs_dsi2dpll_phaselock; 6=hwobs_usbdpll_phaselock
0x45C CONTROL_CONF_DPLL_TENABLE_SEL — dpll_tenable view Access conditions. Read: unrestricted, Write: unrestricted
  [2:0] MULT rw — Select one of the following signals:
    0=hwobs_coredpll_tenable; 1=hwobs_abedpll_tenable; 2=hwobs_perdpll_tenable; 3=hwobs_dsi1dpll_tenable; 4=hwobs_dsi2dpll_tenable; 6=hwobs_usbdpll_tenable
0x460 CONTROL_CONF_DPLL_TENABLEDIV_SEL — dpll_tenablediv view Access conditions. Read: unrestricted, Write: unrestricted
  [2:0] MULT rw — Select one of the following signals:
    0=hwobs_coredpll_tenablediv; 1=hwobs_abedpll_tenablediv; 2=hwobs_perdpll_tenablediv; 3=hwobs_dsi1dpll_tenablediv; 4=hwobs_dsi2dpll_tenablediv; 6=hwobs_usbdpll_tenablediv
0x464 CONTROL_CONF_DPLL_BYPASSACK_SEL — dpll_bypassack view Access conditions. Read: unrestricted, Write: unrestricted
  [2:0] MULT rw — Select one of the following signals:
    0=hwobs_coredpll_bypassack; 1=hwobs_abedpll_bypassack; 2=hwobs_perdpll_bypassack; 3=hwobs_dsi1dpll_bypassack; 4=hwobs_dsi2dpll_bypassack; 6=hwobs_usbdpll_bypassack
0x468 CONTROL_CONF_DPLL_IDLE_SEL — dpll_idle view Access conditions. Read: unrestricted, Write: unrestricted
  [2:0] MULT rw — Select one of the following signals:
    0=hwobs_coredpll_idle; 1=hwobs_abedpll_idle; 2=hwobs_perdpll_idle; 3=hwobs_dsi1dpll_idle; 4=hwobs_dsi2dpll_idle; 6=hwobs_usbdpll_idle
0x480 CONTROL_CORE_CONF_DEBUG_SEL_TST_0 — Select mode for debug port Access conditions. Read: unrestricted, Write: unrestricted
  [3:0] MODE rw — Select one of the following signals:
    0=hwobs_int_mpu_0; 1=clk_view_0; 4=This information is not available in the public domain; 5=hwobs_int_cm2_0; 6=hwobs_int_ivahd_0; 8=hwobs_int_abe_0; 9=This information is not available in the public domain; 12=This information is not available in the public domain
0x484 CONTROL_CORE_CONF_DEBUG_SEL_TST_1 — Select mode for debug port Access conditions. Read: unrestricted, Write: unrestricted
  [3:0] MODE rw — Select one of the following signals:
    0=hwobs_int_mpu_1; 1=clk_view_1; 5=hwobs_int_cm2_1; 6=hwobs_int_ivahd_1; 8=hwobs_int_abe_1; 9=This information is not available in the public domain
0x488 CONTROL_CORE_CONF_DEBUG_SEL_TST_2 — Select mode for debug port Access conditions. Read: unrestricted, Write: unrestricted
  [3:0] MODE rw — Select one of the following signals:
    0=hwobs_int_mpu_2; 1=clk_view_2; 5=hwobs_int_cm2_2; 6=hwobs_int_ivahd_2; 8=hwobs_int_abe_2; 9=This information is not available in the public domain
0x48C CONTROL_CORE_CONF_DEBUG_SEL_TST_3 — Select mode for debug port Access conditions. Read: unrestricted, Write: unrestricted
  [3:0] MODE rw — Select one of the following signals:
    0=hwobs_int_mpu_3; 1=dpll_freqlock; 5=hwobs_int_cm2_3; 6=hwobs_int_ivahd_3; 8=hwobs_int_abe_3; 9=This information is not available in the public domain
0x490 CONTROL_CORE_CONF_DEBUG_SEL_TST_4 — Select mode for debug port Access conditions. Read: unrestricted, Write: unrestricted
  [3:0] MODE rw — Select one of the following signals:
    0=hwobs_int_mpu_4; 1=dpll_tinitz; 5=hwobs_int_cm2_4; 6=hwobs_int_ivahd_4; 8=hwobs_int_abe_4; 9=This information is not available in the public domain
0x494 CONTROL_CORE_CONF_DEBUG_SEL_TST_5 — Select mode for debug port Access conditions. Read: unrestricted, Write: unrestricted
  [3:0] MODE rw — Select one of the following signals:
    0=hwobs_int_mpu_5; 1=dpll_phaselock; 5=hwobs_int_cm2_5; 6=hwobs_int_ivahd_5; 8=hwobs_int_abe_5; 9=This information is not available in the public domain
0x498 CONTROL_CORE_CONF_DEBUG_SEL_TST_6 — Select mode for debug port Access conditions. Read: unrestricted, Write: unrestricted
  [3:0] MODE rw — Select one of the following signals:
    0=hwobs_int_mpu_6; 5=hwobs_int_cm2_6; 6=hwobs_int_ivahd_6; 8=hwobs_int_abe_6; 9=This information is not available in the public domain
0x49C CONTROL_CORE_CONF_DEBUG_SEL_TST_7 — Select mode for debug port Access conditions. Read: unrestricted, Write: unrestricted
  [3:0] MODE rw — Select one of the following signals:
    0=hwobs_int_mpu_7; 1=dpll_tenable; 2=sdma_req_view_0; 5=hwobs_int_cm2_7; 6=hwobs_int_ivahd_7; 8=hwobs_int_abe_7; 9=This information is not available in the public domain
0x4A0 CONTROL_CORE_CONF_DEBUG_SEL_TST_8 — Select mode for debug port Access conditions. Read: unrestricted, Write: unrestricted
  [3:0] MODE rw — Select one of the following signals:
    0=hwobs_int_mpu_8; 1=dpll_tenablediv; 2=sdma_req_view_1; 5=hwobs_int_cm2_8; 6=hwobs_int_ivahd_8; 8=hwobs_int_abe_8; 9=This information is not available in the public domain
0x4A4 CONTROL_CORE_CONF_DEBUG_SEL_TST_9 — Select mode for debug port Access conditions. Read: unrestricted, Write: unrestricted
  [3:0] MODE rw — Select one of the following signals:
    0=hwobs_int_mpu_9; 1=dpll_bypassack; 2=sdma_req_view_2; 5=hwobs_int_cm2_9; 6=hwobs_int_ivahd_9; 8=hwobs_int_abe_9; 9=This information is not available in the public domain; 11=hwobs_dssvenctvdetgp
0x4A8 CONTROL_CORE_CONF_DEBUG_SEL_TST_10 — Select mode for debug port Access conditions. Read: unrestricted, Write: unrestricted
  [3:0] MODE rw — Select one of the following signals:
    0=hwobs_int_mpu_10; 1=dpll_idle; 2=sdma_req_view_3; 5=hwobs_int_cm2_10; 6=hwobs_int_ivahd_10; 8=hwobs_int_abe_10; 9=This information is not available in the public domain; 11=hwobs_dssdacpwrdndaczcvbs_y
0x4AC CONTROL_CORE_CONF_DEBUG_SEL_TST_11 — Select mode for debug port Access conditions. Read: unrestricted, Write: unrestricted
  [3:0] MODE rw — Select one of the following signals:
    0=hwobs_int_mpu_11; 1=hwobs_hsusbotg_sofpulse; 2=sdma_req_view_all; 5=hwobs_int_cm2_11; 6=hwobs_int_ivahd_11; 8=hwobs_int_abe_11; 9=This information is not available in the public domain; 11=hwobs_dssdacpwrdndaczchroma
0x4B0 CONTROL_CORE_CONF_DEBUG_SEL_TST_12 — Select mode for debug port Access conditions. Read: unrestricted, Write: unrestricted
  [3:0] MODE rw — Select one of the following signals:
    0=hwobs_int_mpu_12; 2=hwobs_coredivider_clkout3; 5=hwobs_int_cm2_12; 6=hwobs_int_ivahd_12; 8=hwobs_int_abe_12; 9=This information is not available in the public domain; 11=hwobs_dssdacpwrdndaccvbs
0x4B4 CONTROL_CORE_CONF_DEBUG_SEL_TST_13 — Select mode for debug port Access conditions. Read: unrestricted, Write: unrestricted
  [3:0] MODE rw — Select one of the following signals:
    0=hwobs_int_mpu_13; 2=hwobs_perdivider_clkout4; 5=hwobs_int_cm2_13; 6=hwobs_int_ivahd_13; 8=hwobs_int_abe_13; 9=This information is not available in the public domain; 11=hwobs_dssdacpwrdnbgz
0x4B8 CONTROL_CORE_CONF_DEBUG_SEL_TST_14 — Select mode for debug port Access conditions. Read: unrestricted, Write: unrestricted
  [3:0] MODE rw — Select one of the following signals:
    0=hwobs_int_mpu_14; 2=hwobs_pd_l4_per_per32k_gfclk; 5=hwobs_int_cm2_14; 6=hwobs_int_ivahd_14; 8=hwobs_int_abe_14; 9=This information is not available in the public domain
{0x480+4i} CONTROL_CORE_CONF_DEBUG_SEL_TST_{i} (i=15..25) — Select mode for debug port Access conditions. Read: unrestricted, Write: unrestricted
  [3:0] MODE rw — Select one of the following signals:
    0=hwobs_int_mpu_{i}; 2=0; 5=hwobs_int_cm2_{i}; 6=hwobs_int_ivahd_{i}; 8=hwobs_int_abe_{i}; 9=This information is not available in the public domain
0x4E8 CONTROL_CORE_CONF_DEBUG_SEL_TST_26 — Select mode for debug port Access conditions. Read: unrestricted, Write: unrestricted
  [3:0] MODE rw — Select one of the following signals:
    0=hwobs_int_mpu_26; 2=0; 4=0; 5=hwobs_int_cm2_26; 6=hwobs_int_ivahd_26; 8=hwobs_int_abe_26; 9=This information is not available in the public domain
{0x480+4i} CONTROL_CORE_CONF_DEBUG_SEL_TST_{i} (i=27..30) — Select mode for debug port Access conditions. Read: unrestricted, Write: unrestricted
  [3:0] MODE rw — Select one of the following signals:
    0=hwobs_int_mpu_{i}; 2=0; 4=0; 5=hwobs_int_cm2_{i}; 6=hwobs_int_ivahd_{i}; 8=hwobs_int_abe_{i}; 9=This information is not available in the public domain; 11=0; 12=sdma_req_view_{i-27}
0x4FC CONTROL_CORE_CONF_DEBUG_SEL_TST_31 — Select mode for debug port Access conditions. Read: unrestricted, Write: unrestricted
  [3:0] MODE rw — Select one of the following signals:
    0=hwobs_int_mpu_31; 2=0; 4=0; 5=hwobs_int_cm2_31; 6=hwobs_int_ivahd_31; 8=hwobs_int_abe_31; 9=This information is not available in the public domain; 11=0; 12=sdma_req_view_all
